VERSION ""

BO_ 512 BODY_COMMAND: 4 EON
  SG_ TORQUE_L : 7|16@0- (1,0) [-1000|1000] "" BODYBOARD
  SG_ TORQUE_R : 23|16@0- (1,0) [-1000|1000] "" BODYBOARD

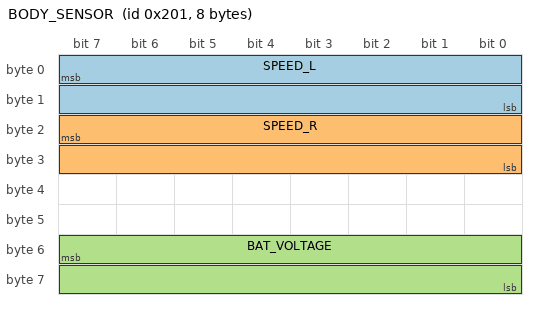
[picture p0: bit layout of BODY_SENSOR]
BO_ 513 BODY_SENSOR: 8 BODYBOARD
  SG_ SPEED_L : 7|16@0- (1,0) [-1000|1000] "" EON
  SG_ SPEED_R : 23|16@0- (1,0) [-1000|1000] "" EON
  SG_ BAT_VOLTAGE : 55|16@0+ (1,0) [0|65535] "" EON
